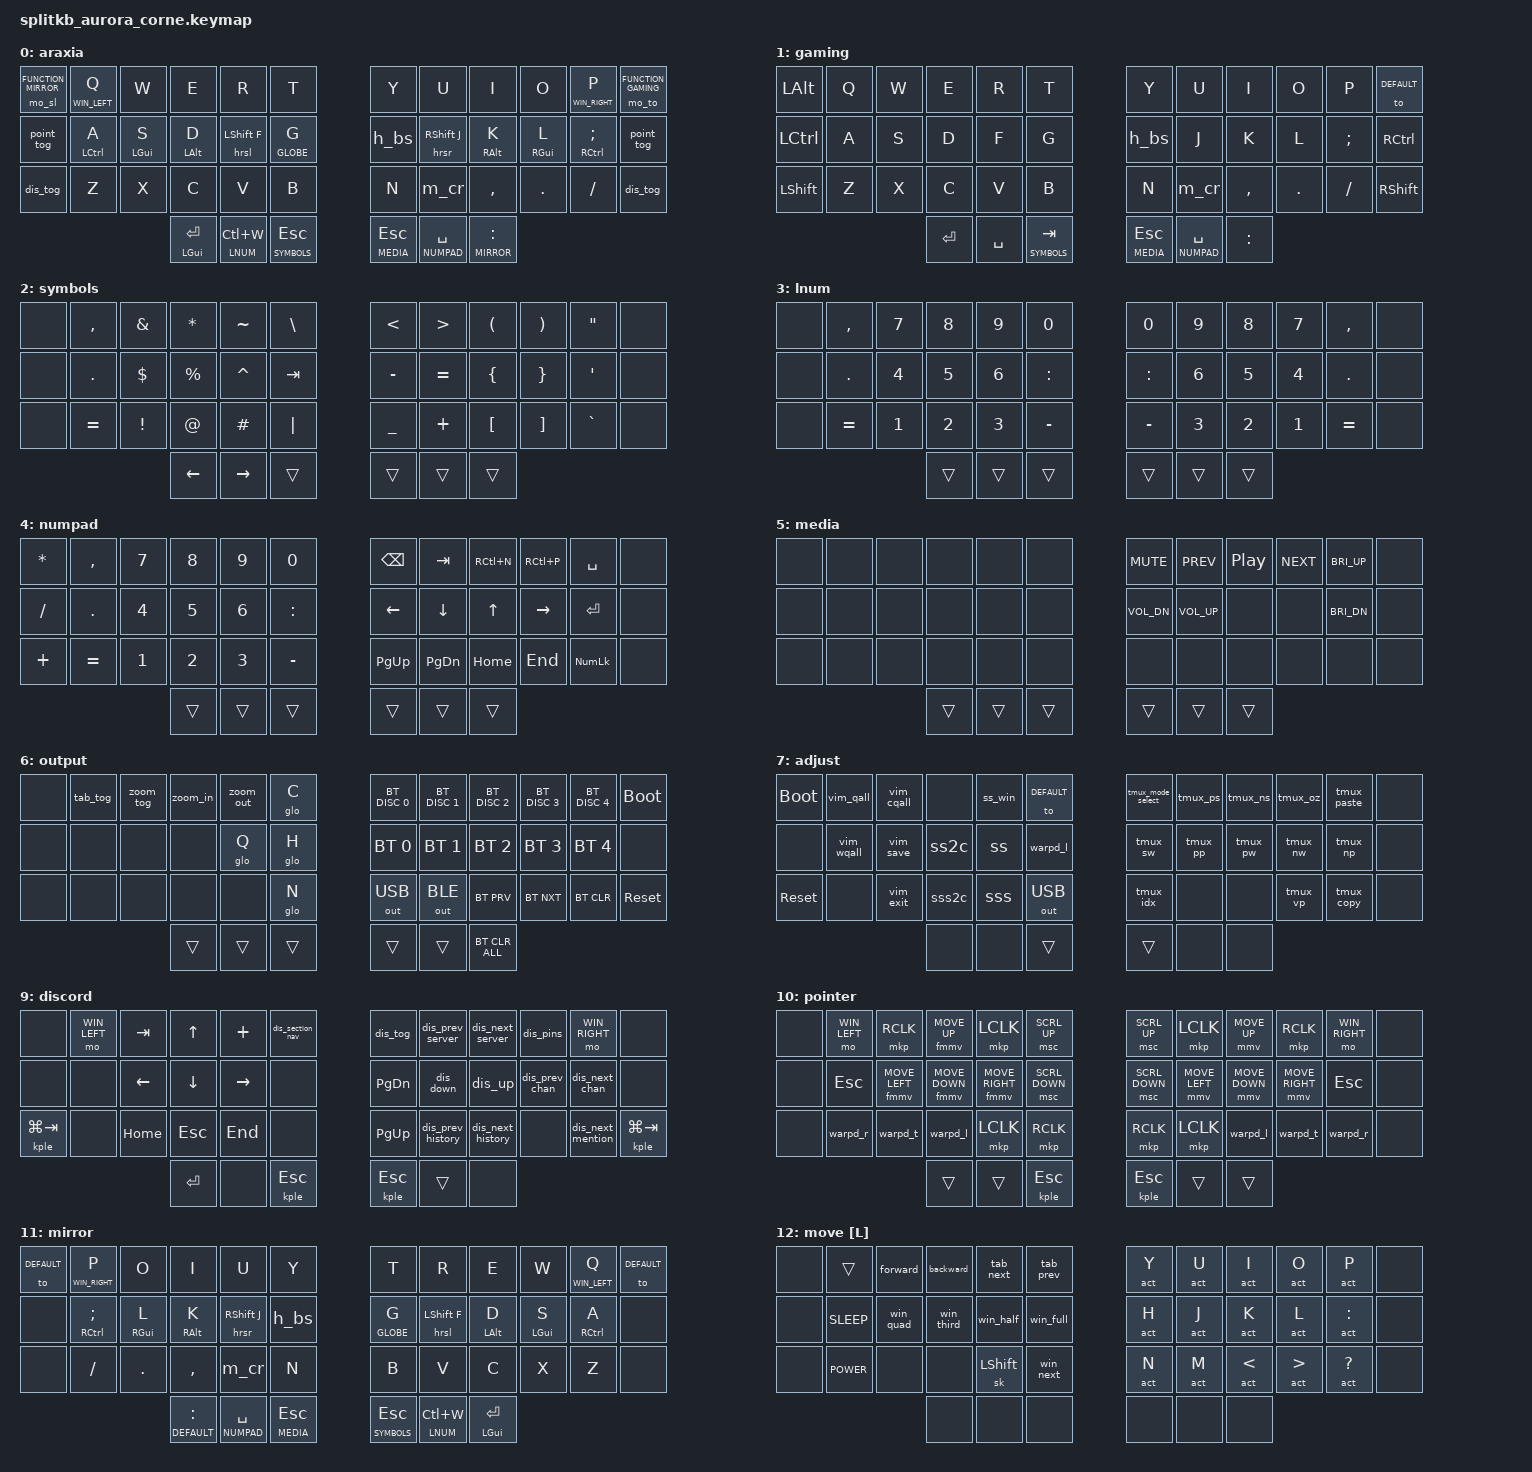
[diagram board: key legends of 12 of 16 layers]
// HEADERS {{{
#include <behaviors.dtsi>
#include <dt-bindings/zmk/keys.h>
#include <dt-bindings/zmk/outputs.h>
#include <dt-bindings/zmk/bt.h>
#include <dt-bindings/zmk/mouse.h>
#include <dt-bindings/zmk/rgb.h>
#include <dt-bindings/zmk/ext_power.h>

#include "shared.dtsi"

// }}}
// CONFIG {{{

&led_strip {
    chain-length = <21>;
};

&sensors {
    triggers-per-rotation = <40>;
};

&nice_view_spi {
    //cs-gpios = <&gpio1 1 GPIO_ACTIVE_HIGH>;
    cs-gpios = <&gpio0 8 GPIO_ACTIVE_HIGH>;
};

// }}}
/ {
// KEYMAP {{{
// n.b. display-name strings are truncated after 8 characters
    keymap {
        compatible = "zmk,keymap";

        /* 0 Layer */
        default {
            display-name = "araxia";
            bindings = <
 &mo_sl FUNCTION MIRROR  &lttp WIN_LEFT Q  &kp W         &kp E              &kp R             &kp T                &kp Y            &kp U               &kp I               &kp O         &lttp WIN_RIGHT P  &mo_to FUNCTION GAMING
 &point_tog              &hrml LCTRL A     &hrml LGUI S  &hrml LALT D       &hrsl LSHIFT F    &hrml GLOBE G        &h_bs            &hrsr RSHIFT J      &hrmr RALT K        &hrmr RGUI L  &hrmr RCTRL SEMI   &point_tog
 &dis_tog                &kp Z             &kp X         &kp C              &kp V             &kp B                &kp N            &m_cr               &kp COMMA           &kp DOT       &kp SLASH          &dis_tog
                                                         &mthp LGUI RETURN  &lthp LNUM LC(W)  &lthp SYMBOLS ESC    &lthp MEDIA ESC  &lttp NUMPAD SPACE  &lthp MIRROR COLON
            >;
            //sensor-bindings = <&inc_dec_kp C_VOL_DN C_VOL_UP &inc_dec_kp PG_UP PG_DN>;
            sensor-bindings = <&inc_dec_kp PG_UP PG_DN &inc_dec_kp C_VOL_DN C_VOL_UP>;
        };

        /* 1 Layer */
        gaming {
            display-name = "gaming";
            bindings = <
 &kp LALT    &kp Q  &kp W  &kp E       &kp R      &kp T                &kp Y            &kp U               &kp I      &kp O    &kp P      &to DEFAULT
 &kp LCTRL   &kp A  &kp S  &kp D       &kp F      &kp G                &h_bs            &kp J               &kp K      &kp L    &kp SEMI   &kp RCTRL
 &kp LSHIFT  &kp Z  &kp X  &kp C       &kp V      &kp B                &kp N            &m_cr               &kp COMMA  &kp DOT  &kp SLASH  &kp RSHIFT
                           &kp RETURN  &kp SPACE  &lthp SYMBOLS TAB    &lthp MEDIA ESC  &lttp NUMPAD SPACE  &kp COLON
            >;
        };

        /* 2 Layer */
        symbols {
            display-name = "symbols";
            bindings = <
&none  &kp COMMA  &kp AMPERSAND    &kp ASTERISK  &kp TILDE   &kp BACKSLASH     &kp LESS_THAN   &kp GREATER_THAN  &kp LEFT_PARENTHESIS  &kp RIGHT_PARENTHESIS  &kp DOUBLE_QUOTES  &none
&none  &kp DOT    &kp DOLLAR       &kp PERCENT   &kp CARET   &kp TAB           &kp MINUS       &kp EQUAL         &kp LEFT_BRACE        &kp RIGHT_BRACE        &kp SINGLE_QUOTE   &none
&none  &kp EQUAL  &kp EXCLAMATION  &kp AT        &kp POUND   &kp PIPE          &kp UNDERSCORE  &kp PLUS          &kp LEFT_BRACKET      &kp RIGHT_BRACKET      &kp GRAVE          &none
                                   &kp LEFT      &kp RIGHT   &trans            &trans          &trans            &trans
            >;
        };

        /* 3 Layer */
        lnum {
            display-name = "lnum";
            bindings = <
&none  &kp COMMA  &kp N7  &kp N8  &kp N9  &kp N0        &kp N0     &kp N9  &kp N8  &kp N7  &kp COMMA  &none
&none  &kp DOT    &kp N4  &kp N5  &kp N6  &kp COLON     &kp COLON  &kp N6  &kp N5  &kp N4  &kp DOT    &none
&none  &kp EQUAL  &kp N1  &kp N2  &kp N3  &kp MINUS     &kp MINUS  &kp N3  &kp N2  &kp N1  &kp EQUAL  &none
                          &trans  &trans  &trans        &trans     &trans  &trans
            >;
        };

        /* 4 Layer */
        numpad {
            display-name = "numpad";
            bindings = <
&kp ASTERISK  &kp COMMA  &kp N7  &kp N8  &kp N9  &kp N0        &kp BACKSPACE  &kp TAB        &kp RC(N)  &kp RC(P)  &kp SPACE       &none
&kp SLASH     &kp DOT    &kp N4  &kp N5  &kp N6  &kp COLON     &kp LEFT       &kp DOWN       &kp UP     &kp RIGHT  &kp RETURN      &none
&kp PLUS      &kp EQUAL  &kp N1  &kp N2  &kp N3  &kp MINUS     &kp PAGE_UP    &kp PAGE_DOWN  &kp HOME   &kp END    &kp KP_NUMLOCK  &none
                                 &trans  &trans  &trans        &trans         &trans         &trans
            >;
        };

        /* 5 Layer */
        media {
            display-name = "media";
            bindings = <
&none  &none  &none  &none   &none   &none     &kp C_MUTE    &kp C_PREV    &kp C_PP      &kp C_NEXT    &kp C_BRI_UP  &none
&none  &none  &none  &none   &none   &none     &kp C_VOL_DN  &kp C_VOL_UP  &none         &none         &kp C_BRI_DN  &none
&none  &none  &none  &none   &none   &none     &none         &none         &none         &none         &none         &none
                     &trans  &trans  &trans    &trans        &trans        &trans
            >;
        };

        /* 6 Layer */
        output {
            display-name = "output";
            bindings = <
&none  &tab_tog  &zoom_tog  &zoom_in  &zoom_out  &glo C     &bt BT_DISC 0 &bt BT_DISC 1 &bt BT_DISC 2 &bt BT_DISC 3   &bt BT_DISC 4  &bootloader
&none  &none     &none      &none     &glo Q     &glo H     &bt BT_SEL 0  &bt BT_SEL 1  &bt BT_SEL 2  &bt BT_SEL 3    &bt BT_SEL 4   &none
&none  &none     &none      &none     &none      &glo N     &out OUT_USB  &out OUT_BLE  &bt BT_PRV    &bt BT_NXT      &bt BT_CLR     &sys_reset
                            &trans    &trans     &trans     &trans        &trans        &bt BT_CLR_ALL
            >;
        };

        /* 7 Layer */
        adjust {
            display-name = "adjust";
            bindings = <
&bootloader  &vim_qall   &vim_cqall  &none   &ss_win  &to DEFAULT      &tmux_mode_select  &tmux_ps  &tmux_ns  &tmux_oz  &tmux_paste  &none
&none        &vim_wqall  &vim_save   &ss2c   &ss      &warpd_l         &tmux_sw           &tmux_pp  &tmux_pw  &tmux_nw  &tmux_np     &none
&sys_reset   &none       &vim_exit   &sss2c  &sss     &out OUT_USB     &tmux_idx          &none     &none     &tmux_vp  &tmux_copy   &none
                                     &none   &none    &trans           &trans             &none     &none
            >;
        };

        /* 8 Layer */
        /* Do not use this then-layer for regular layer switching */
        lighting {
            display-name = "lighting";
            bindings = <
&none   &trans  &rgb_ug RGB_TOG  &rgb_ug RGB_BRI  &rgb_ug RGB_BRD  &rgb_ug RGB_COLOR_HSB(25,100,0)      &ext_power EP_TOG  &none  &none  &none  &trans &none
&none   &none   &none            &rgb_ug RGB_SAI  &rgb_ug RGB_SAD  &rgb_ug RGB_COLOR_HSB(25,100,80)     &none              &none  &none  &none  &none  &none
&none   &none   &none            &rgb_ug RGB_HUI  &rgb_ug RGB_HUD  &rgb_ug RGB_COLOR_HSB(25,0,100)      &none              &none  &none  &none  &none  &none
                                 &none            &none            &none                                &none              &none  &none
            >;
        };

        /* 9 Layer */
        discord {
            display-name = "discord";
            bindings = <
&none         &mo WIN_LEFT  &kp TAB   &kp UP      &kp PLUS   &dis_section_nav    &dis_tog       &dis_prev_server      &dis_next_server       &dis_pins       &mo WIN_RIGHT      &none
&none         &none         &kp LEFT  &kp DOWN    &kp RIGHT  &none               &kp PAGE_DOWN  &dis_down             &dis_up                &dis_prev_chan  &dis_next_chan     &none
&kple LG(TAB) &none         &kp HOME  &kp ESC     &kp END    &none               &kp PAGE_UP    &dis_prev_history     &dis_next_history      &none           &dis_next_mention  &kple LG(TAB)
                                      &kp RETURN  &none      &kple ESC           &kple ESC      &trans                &none
            >;
            sensor-bindings = <&rot_msc MOVE_X(40) MOVE_X(-40) &rot_msc MOVE_Y(40) MOVE_Y(-40)>;
        };

        /* 10 Layer */
        pointer {
            display-name = "pointer";
            bindings = <
&none  &mo WIN_LEFT  &mkp RCLK        &fmmv MOVE_UP    &mkp LCLK         &msc SCRL_UP      &msc SCRL_UP    &mkp LCLK       &mmv MOVE_UP    &mkp RCLK        &mo WIN_RIGHT  &none
&none  &kp ESC       &fmmv MOVE_LEFT  &fmmv MOVE_DOWN  &fmmv MOVE_RIGHT  &msc SCRL_DOWN    &msc SCRL_DOWN  &mmv MOVE_LEFT  &mmv MOVE_DOWN  &mmv MOVE_RIGHT  &kp ESC        &none
&none  &warpd_r      &warpd_t         &warpd_l         &mkp LCLK         &mkp RCLK         &mkp RCLK       &mkp LCLK       &warpd_l        &warpd_t         &warpd_r       &none
                                      &trans           &trans            &kple ESC         &kple ESC       &trans          &trans
            >;
            sensor-bindings = <&rot_msc MOVE_X(40) MOVE_X(-40)>;
        };

        /* 11 Layer */
        mirror {
            display-name = "mirror";
            bindings = <
 &to DEFAULT  &lttp WIN_RIGHT P  &kp O         &kp I                &kp U               &kp Y              &kp T              &kp R             &kp E              &kp W         &lttp WIN_LEFT Q  &to DEFAULT
 &none        &hrmr RCTRL SEMI   &hrmr RGUI L  &hrmr RALT K         &hrsr RSHIFT J      &h_bs              &hrml GLOBE G      &hrsl LSHIFT F    &hrml LALT D       &hrml LGUI S  &hrml RCTRL A     &none
 &none        &kp SLASH          &kp DOT       &kp COMMA            &m_cr               &kp N              &kp B              &kp V             &kp C              &kp X         &kp Z             &none
                                               &lthp DEFAULT COLON  &lthp NUMPAD SPACE  &lthp MEDIA ESC    &lthp SYMBOLS ESC  &lthp LNUM LC(W)  &mthp LGUI RETURN
            >;
        };

        /* 12 Layer */
        window_left {
            display-name = "move [L]";
            bindings = <
&none  &trans       &forward   &backward   &tab_next   &tab_prev    &act Y  &act U  &act I          &act O             &act P         &none
&none  &kp C_SLEEP  &win_quad  &win_third  &win_half   &win_full    &act H  &act J  &act K          &act L             &act COLON     &none
&none  &kp C_POWER  &none      &none       &sk LSHIFT  &win_next    &act N  &act M  &act LESS_THAN  &act GREATER_THAN  &act QUESTION  &none
                               &none       &none       &none        &none   &none   &none
            >;
        };

        /* 13 Layer */
        window_right {
            display-name = "move [R]";
            bindings = <
&none  &act Q  &act W  &act E  &act R  &act T    &tab_prev   &tab_next   &backward   &forward   &trans       &none
&none  &act A  &act S  &act D  &act F  &act G    &win_full   &win_half   &win_third  &win_quad  &kp C_SLEEP  &none
&none  &act Z  &act X  &act C  &act V  &act B    &win_next   &sk RSHIFT  &none       &none      &kp C_POWER  &none
                       &none   &none   &none     &none       &none       &none
            >;
        };

        /* 14 Layer */
        act {
            display-name = "act";
            bindings = <
&none  &act Q  &act W  &act E  &act R  &act T     &act Y  &act U  &act I          &act O             &act P         &none
&none  &act A  &act S  &act D  &act F  &act G     &act H  &act J  &act K          &act L             &act COLON     &none
&none  &act Z  &act X  &act C  &act V  &act B     &act N  &act M  &act LESS_THAN  &act GREATER_THAN  &act QUESTION  &none
                       &trans  &trans  &trans     &trans  &trans  &trans
            >;
        };

        /* 15 Layer */
        func {
            display-name = "func";
            bindings = <
&none  &kp F1  &kp F2   &kp F3   &kp F4   &f2_menu      &help_menu  &kp F13   &kp F14   &kp F15    &kp F16  &none
&none  &kp F5  &kp F6   &kp F7   &kp F8   &f2_status    &point_tog  &kp F17   &kp F18   &kp F19    &kp F20  &none
&none  &kp F9  &kp F10  &kp F11  &kp F12  &f2_dock      &dis_tog    &kp F21   &kp F22   &kp F23    &kp F24  &none
                        &trans   &trans   &trans        &trans      &trans    &trans
            >;
        };

    };

};
// }}}
/* vim: set ft=dts: */
